# gpadc_ctrl_secure register map
Vendor: Texas Instruments
Peripheral module from a debugger description file (folder CC35X1E).
Registers are 32-bit, access per field, reset 0x0 unless marked. A register's access mark holds for its fields unless they carry their own. Offsets are as the file gives them; lines under a group give offsets from that group; [hi:lo] are bit positions; {n}, {i} and the like mark numbered series; 'fields as' and 'values as' point back to an identical list; <NAME> marks a mode.

## gpadc_ctrl_secure
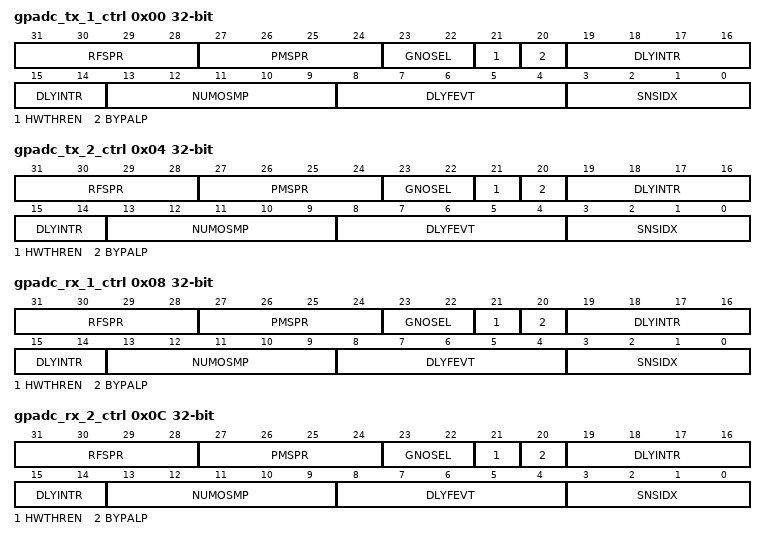
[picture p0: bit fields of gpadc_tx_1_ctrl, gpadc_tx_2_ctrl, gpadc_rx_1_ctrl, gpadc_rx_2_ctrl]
0x00 gpadc_tx_1_ctrl rw reset not defined — GPADC TX 1 CONTROL TX set 1 control register
  [31:28] RFSPR — RFCIO spare dynamic bits
  [27:24] PMSPR — PMCIO spare dynamic bits
  [23:22] GNOSEL — GAIN OUT SELECT '00' - chooses del_vbe_buf_outm '01' - chooses del_vbe_buf_outp '10' - chooses diffrential both p and m '11' - NA
  [21] HWTHREN — HARDWARE THRESHOLD ENABLE enble the comparators block to compare sample to HW threshold
  [20] BYPALP — BYPASS ALPHA FILTER Alpha filter block indication, bypass the alpha filter for the first sample
  [19:14] DLYINTR — DELAY INTERVAL Full span 0..63 *12.8us, jumps in 12.8us, up to ~793.6us Full span 0..63 *13.6us, jumps in 13.6us, up to ~843.2us Full span 0..63 *16us, jumps in 16us, up to ~992us Full span 0..63 *19.2us, jumps in 19.2us, up to ~1190.4us *note - 1 ganulation cycle need to be kept between 2 Agents 0 - Continues Mode (with gaps of 1 GPADC clk cycle between each number of samples) 1 - 12.8 us 2 - 25.6us 3 - 38.4us ... 62 - 793.6us 63 - Single shot [one sample]
  [13:9] NUMOSMP — NUMBER OF SAMPLES Full span 0..31 *1.6us, jumps in 1.6us, up to ~49.6us Full span 0..31 *1.7us, jumps in 1.7us, up to ~52.7us Full span 0..31 *2us, jumps in 2us, up to ~62us Full span 0..31 *2.4us, jumps in 2.4us, up to ~74.4us *note - 1 ganulation cycle need to be kept between 2 Agents 0 - not allowed 1 - 1.6us 2 - 3.2us 3 - 4.8us ... 31 - 49.6us
  [8:4] DLYFEVT — DELAY FROM EVENT Full span 0..31 *1.6us, jumps in 1.6us, up to ~49.6us Full span 0..31 *1.7us, jumps in 1.7us, up to ~52.7us Full span 0..31 *2us, jumps in 2us, up to ~62us Full span 0..31 *2.4us, jumps in 2.4us, up to ~74.4us *note - 1 ganulation cycle (1.6/1.7/2.0/2.4 us) need to be kept between 2 Agents 0 - 0.5us - minimum value. 1 - 1.6us 2 - 3.2us 3 - 4.8us ... 31 - 49.6us *note- delay from event is not accurate, additional of up to 200ns might be added.
  [3:0] SNSIDX — SENSOR INDEX 0 - ATB 1 - Vdd_Main 2 - Vdd_PA 3 - Thermal Protection 4 - Thermal Calibration 5 - Env_Det_Calibration 6 - BG Blocker 7 - PM BIST 8 - RFCIO TEST_M 9 - RFCIO TEST_P (using thermal protectio sens sel only) 10 - PM BG 0.9V 11 - PM BG 1.22V 12 - I2V_VOUT 13 - SPARE2 14 - IS_RX_FILTER
0x04 gpadc_tx_2_ctrl rw reset not defined — GPADC TX 2 CONTROL TX set 2 control register
  fields as gpadc_tx_1_ctrl
0x08 gpadc_rx_1_ctrl rw reset not defined — GPADC RX 1 CONTROL RX set 3 control register
  fields as gpadc_tx_1_ctrl
0x0C gpadc_rx_2_ctrl rw reset not defined — GPADC RX 2 CONTROL RX set 4 control register
  fields as gpadc_tx_1_ctrl
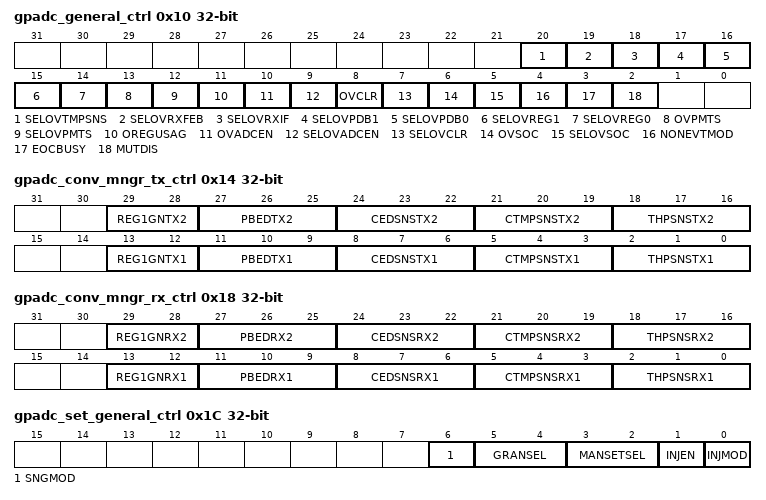
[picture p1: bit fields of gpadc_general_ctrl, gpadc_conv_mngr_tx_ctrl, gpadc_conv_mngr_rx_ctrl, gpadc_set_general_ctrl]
0x10 gpadc_general_ctrl reset not defined — GPADC general control
  [20] SELOVTMPSNS rw — SELECT OVERRIDE TEMPRATURE SENSOR WLAN '0' - No GPADC CTRL '1' - GPADC CTRL output regs usage
  [19] SELOVRXFEB rw — SELECT OVERRIDE RXFEB REG4 '0' - No GPADC CTRL '1' - GPADC CTRL output regs usage
  [18] SELOVRXIF rw — SELECT OVERRIDE RXIF '0' - No GPADC CTRL '1' - GPADC CTRL output regs usage
  [17] SELOVPDB1 rw — SELECT OVERRIDE POWER DETECT BUFFER REGISTER 1 '0' - No GPADC CTRL '1' - GPADC CTRL output regs usage
  [16] SELOVPDB0 rw — SELECT OVERRIDE POWER DETECT BUFFER REGISTER 0 '0' - No GPADC CTRL '1' - GPADC CTRL output regs usage
  [15] SELOVREG1 rw — SELECT OVERRIDE REGISTER 1 '0' - No GPADC CTRL '1' - GPADC CTRL output regs usage
  [14] SELOVREG0 rw — SELECT OVERRIDE REGISTER 0 '0' - No GPADC CTRL '1' - GPADC CTRL output regs usage
  [13] OVPMTS rw — OVERRIDE PMCIO TEMP SENSOR overide value
  [12] SELOVPMTS rw — SELCT OVERRIDE PMCIO TEMP SENSOR '0' - No GPADC CTRL '1' - GPADC CTRL output regs usage
  [11] OREGUSAG rw — OUTPUT REGISTER USAGE LX PG1 and PG2 use only, for boot measurements. after boot should be set '1'. GPADC_REG0 and GPADC_REG1 control only. '0' - No GPADC CTRL '1' - GPADC CTRL output regs usage
  [10] OVADCEN rw — OVERRIDE ADC ENABLE overide value
  [9] SELOVADCEN rw — SELECT OVERRIDE ADC EN '1' - uses overide value '0' - use regular operation
  [8] OVCLR rw — OVERRIDE CLEAR overide value
  [7] SELOVCLR rw — SELCT OVERRIDE CLEAR '1' - uses overide value '0' - use regular operation
  [6] OVSOC rw — OVERRIDE START OF CONVERSION '1' - uses overide value '0' - use regular operation
  [5] SELOVSOC rw — SELECT OVERRIDE START OF CONVERSION '1' - uses overide value '0' - use regular operation
  [4] NONEVTMOD rw — NONE EVENT MODE '1' - for using only RX set 1. ignors the TX transition. '0' - regular operation Process to operate NON EVENT MODE: 1. Disable ALL SETs. 2. config RX SETs 3. Enable NON EVENT MODE 4. Enable RX SETs 5. once measurement has finished, Disable all SETs and reconfigure 6. Disable NON EVENT MODE 7. Enable SETs
  [3] EOCBUSY ro — adc end of conversion (busy) indication
  [2] MUTDIS rw — MUTE DISABLE '1' - disables the line mute output
0x14 gpadc_conv_mngr_tx_ctrl — Conversion Manager registers tx control set
  [29:28] REG1GNTX2 rw — REGISTER 1 GAIN TX 2 holds the configuration of the gpadc_reg1 gain: SE '11' (1000) - 2 (~6db) '10' (0100) - 1.75 '01' (0010) - 1.5 (~3.5db) '00' (0001) - 1 (0db) DIFF '11' (1000) - 2 (~6db) '10' (0100) - 1.5 (~3.5db) '01' (0010) - 1 (0db) '00' (0001) - NU
  [27:25] PBEDTX2 rw — POWER DETECT BUFFER ENVELOP DETECTOR TX 2 DIFF mode: '000' - 8 '001' - 5 '010' - 4 '011' - 2 '100' - 1 '101' - 0.5 SE mode: '000' - 4 '001' - 2.5 '010' - 2 '011' - 1 '100' - 0.5 '101' - 0.25
  [24:22] CEDSNSTX2 rw — CALIBRATION ENVELOP DETECTOR SENSOR SELECT TX 2 holds the configuration of the specific env_det sensor that calibration wish to convert
  [21:19] CTMPSNSTX2 rw — CALIBRATION TEMPRATURE SENSORE TX 2 holds the configuration of the specific thermal sensor that calibration wish to convert
  [18:16] THPSNSTX2 rw — THERMAL PROTECTION SENSOR TX 2 holds the configuration of the specific thermal sensor that thermal protection wish to convert
  [13:12] REG1GNTX1 rw — REGISTER 1 GAIN TX 1 holds the configuration of the gpadc_reg1 gain: SE '11' (1000) - 2 (~6db) '10' (0100) - 1.75 '01' (0010) - 1.5 (~3.5db) '00' (0001) - 1 (0db) DIFF '11' (1000) - 2 (~6db) '10' (0100) - 1.5 (~3.5db) '01' (0010) - 1 (0db) '00' (0001) - NU
  [11:9] PBEDTX1 rw — POWER DETECT BUFFER ENVELOP DETECTOR TX 1 DIFF mode: '000' - 8 '001' - 5 '010' - 4 '011' - 2 '100' - 1 '101' - 0.5 SE mode: '000' - 4 '001' - 2.5 '010' - 2 '011' - 1 '100' - 0.5 '101' - 0.25
  [8:6] CEDSNSTX1 rw — CALIBRATION ENVELOP DETECTOR SENSOR SELECT TX 1 holds the configuration of the specific env_det sensor that calibration wish to convert
  [5:3] CTMPSNSTX1 rw — CALIBRATION TEMPRATURE SENSORE TX 1 holds the configuration of the specific thermal sensor that calibration wish to convert
  [2:0] THPSNSTX1 rw — THERMAL PROTECTION SENSOR TX 1 holds the configuration of the specific thermal sensor that thermal protection wish to convert
0x18 gpadc_conv_mngr_rx_ctrl — Conversion Manager registers rx control set
  [29:28] REG1GNRX2 rw — REGISTER 1 GAIN RX 2 holds the configuration of the gpadc_reg1 gain: SE '11' (1000) - 2 (~6db) '10' (0100) - 1.75 '01' (0010) - 1.5 (~3.5db) '00' (0001) - 1 (0db) DIFF '11' (1000) - 2 (~6db) '10' (0100) - 1.5 (~3.5db) '01' (0010) - 1 (0db) '00' (0001) - NU
  [27:25] PBEDRX2 rw — POWER DETECT BUFFER ENVELOP DETECTOR RX 2 DIFF mode: '000' - 8 '001' - 5 '010' - 4 '011' - 2 '100' - 1 '101' - 0.5 SE mode: '000' - 4 '001' - 2.5 '010' - 2 '011' - 1 '100' - 0.5 '101' - 0.25
  [24:22] CEDSNSRX2 rw — CALIBRATION ENVELOP DETECTOR SENSOR SELECT RX 2 holds the configuration of the specific env_det sensor that calibration wish to convert
  [21:19] CTMPSNSRX2 rw — CALIBRATION TEMPRATURE SENSORE RX 2 holds the configuration of the specific thermal sensor that calibration wish to convert
  [18:16] THPSNSRX2 rw — THERMAL PROTECTION SENSOR RX 2 holds the configuration of the specific thermal sensor that thermal protection wish to convert
  [13:12] REG1GNRX1 rw — REGISTER 1 GAIN RX 1 holds the configuration of the gpadc_reg1 gain: SE '11' (1000) - 2 (~6db) '10' (0100) - 1.75 '01' (0010) - 1.5 (~3.5db) '00' (0001) - 1 (0db) DIFF '11' (1000) - 2 (~6db) '10' (0100) - 1.5 (~3.5db) '01' (0010) - 1 (0db) '00' (0001) - NU
  [11:9] PBEDRX1 rw — POWER DETECT BUFFER ENVELOP DETECTOR RX 1 DIFF mode: '000' - 8 '001' - 5 '010' - 4 '011' - 2 '100' - 1 '101' - 0.5 SE mode: '000' - 4 '001' - 2.5 '010' - 2 '011' - 1 '100' - 0.5 '101' - 0.25
  [8:6] CEDSNSRX1 rw — CALIBRATION ENVELOP DETECTOR SENSOR SELECT RX 1 holds the configuration of the specific env_det sensor that calibration wish to convert
  [5:3] CTMPSNSRX1 rw — CALIBRATION TEMPRATURE SENSORE RX 1 holds the configuration of the specific thermal sensor that calibration wish to convert
  [2:0] THPSNSRX1 rw — THERMAL PROTECTION SENSOR RX 1 holds the configuration of the specific thermal sensor that thermal protection wish to convert
0x1C gpadc_set_general_ctrl — SETS GENERAL CONTROL
  [6] SNGMOD rw — SINGLE MODE Force clear @adc_soc for each sample (1.6us); Defaul is 0 (Continous mode).
  [5:4] GRANSEL rw — GRANULATION SELECT defines the GPADC granulation 0 - 1.6us 1 - 1.7us 2 - 2us 3 - 2.4us
  [3:2] MANSETSEL rw — MANUAL SET SELECTOR during debug a user would like to set the set selector 00 - RX A 01 - RX B 10 - TX A 11 - TX B
  [1] INJEN rw — INJECT ENABLE when '1' use Inject mode '1' - use manual set selector
  [0] INJMOD rw — INJECT MODE when '1' user config the mode : Manual (0) vs. Auto (1). Default is manual
0x20 gpadc_m0_irq_mask_ctrl — M0 INTERRUPT BIT MASK M0 IRQ MASK registers control set
  [7:0] VAL rw — VALUE 1 - mask the event; 0 - do not mask. Event will cause IRQ '00000001' - tx set 1 high '00000010' - tx set 2 high '00000100' - rx set 1 high '00001000' - rx set 2 high '00010000' - tx set 1 low '00100000' - tx set 2 low '01000000' - rx set 1 low '10000000' - rx set 2 low
0x24 gpadc_m0_irq_status ro — M0 IRQ status register
  [7:0] VAL — VALUE M0 IRQ status register; clear upon read by S/W '00000001' - tx set 1 high '00000010' - tx set 2 high '00000100' - rx set 1 high '00001000' - rx set 2 high '00010000' - tx set 1 low '00100000' - tx set 2 low '01000000' - rx set 1 low '10000000' - rx set 2 low
0x28 gpadc_m3_irq_mask_ctrl — M3 INTERRUPT BIT MASK M3 IRQ MASK registers control set
  fields as gpadc_m0_irq_mask_ctrl
0x2C gpadc_m3_irq_status ro — M3 IRQ status register
  fields as gpadc_m0_irq_status
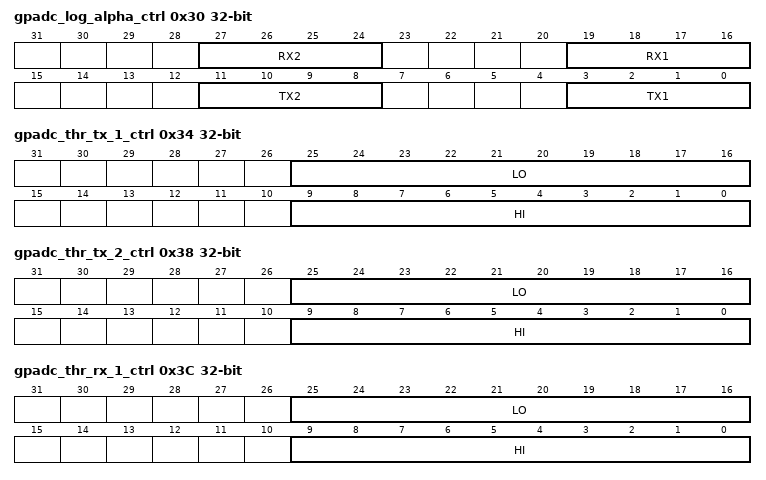
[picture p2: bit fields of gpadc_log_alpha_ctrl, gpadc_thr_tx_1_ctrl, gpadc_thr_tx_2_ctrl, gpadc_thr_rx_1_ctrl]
0x30 gpadc_log_alpha_ctrl — LOG ALPHA GPADC Log Alpha cntrol reister Alpha value = 2^(-mem_) for example if mem_= 1 then alpha is 0.5. Y(n)= (1-alpha)*Y(n-1)+(alpha)*X(n)=Y(n-1)+(alpha)*(X(n)-Y(n-1))
  [27:24] RX2 rw — log alpha rx 2 value
  [19:16] RX1 rw — log alpha rx 1 value
  [11:8] TX2 rw — log alpha tx 2 value
  [3:0] TX1 rw — log alpha tx 1 value
0x34 gpadc_thr_tx_1_ctrl — THRESHOLD TX 1 defines threshold values for tx set 1
  [25:16] LO rw — defines low threshold value for tx set 1
  [9:0] HI rw — defines high threshold value for tx set 1
0x38 gpadc_thr_tx_2_ctrl — THRESHOLD TX 2 defines threshold values for tx set 1
  [25:16] LO rw — defines low threshold value for tx set 2
  [9:0] HI rw — defines high threshold value for tx set 2
0x3C gpadc_thr_rx_1_ctrl — THRESHOLD RX 1 defines threshold values for rx set 1
  [25:16] LO rw — defines low threshold value for rx set 1
  [9:0] HI rw — defines high threshold value for rx set 1
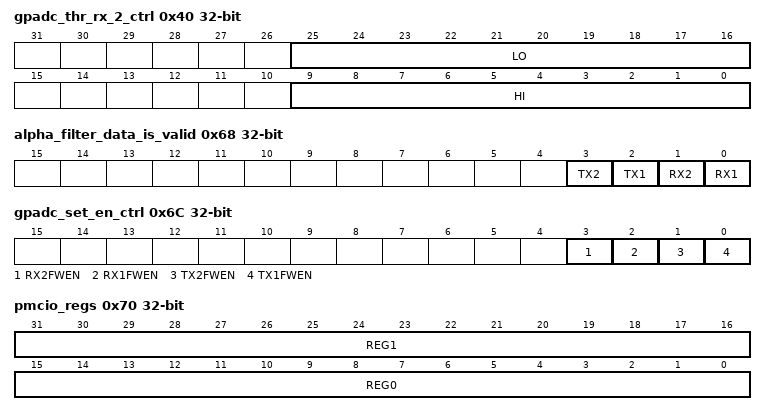
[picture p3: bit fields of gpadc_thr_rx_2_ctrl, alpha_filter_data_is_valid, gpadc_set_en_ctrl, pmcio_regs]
0x40 gpadc_thr_rx_2_ctrl — THRESHOLD RX 2 defines threshold values for rx set 2
  [25:16] LO rw — defines low threshold value for rx set 2
  [9:0] HI rw — defines high threshold value for rx set 2
0x44 gpadc_hw_thermal_thr_ctrl — HARDWARE THERMAL THRESHOLD defines hw thermal threshold value
  [9:0] VAL rw — VALUE hw thermal threshold value
0x48 gpadc_line_mute — LINE MUTE line mute registers control set
  [0] SET rw — SET write clear line mute result - S/W wr option
0x4C gpadc_alpha_res_tx_1 — Alpha result registers control set
  [9:0] SET rw — SET write clear ADC alpha filter result - S/W wr option
0x50 gpadc_alpha_res_tx_2 — Alpha result registers control set
  fields as gpadc_alpha_res_tx_1
0x54 gpadc_alpha_res_rx_1 — Alpha result registers control set
  fields as gpadc_alpha_res_tx_1
0x58 gpadc_alpha_res_rx_2 — Alpha result registers control set
  fields as gpadc_alpha_res_tx_1
0x64 gpadc_adc_sample_ctrl reset 0x40100 — SAMPLE CONTROL
  [9:0] SET rw — SET write clear ADC Sample - S/W wr option
0x68 alpha_filter_data_is_valid ro — ALPHA FILTER DATA VALID Alpha result registers control set
  [3] TX2 — alpha filter data is valid tx 2
  [2] TX1 — alpha filter data is valid tx 1
  [1] RX2 — alpha filter data is valid rx 2
  [0] RX1 — alpha filter data is valid rx 1
0x6C gpadc_set_en_ctrl — SET ENABLE CONTROL GPADC FW EN for each set
  [3] RX2FWEN rw — FIRMWARE ENABLE Enable indication for RX set 2 note: Between disable to enable must save min delay of 0.1us
  [2] RX1FWEN rw — FIRMWARE ENABLE Enable indication for RX set 1 note: Between disable to enable must save min delay of 0.1us
  [1] TX2FWEN rw — FIRMWARE ENABLE Enable indication for TX set 2 note: Between disable to enable must save min delay of 0.1us
  [0] TX1FWEN rw — FIRMWARE ENABLE Enable indication for TX set 1 note: Between disable to enable must save min delay of 0.1us
0x70 pmcio_regs rw
  [31:16] REG1 — REGISTER1
  [15:0] REG0 — REGISTER 0
